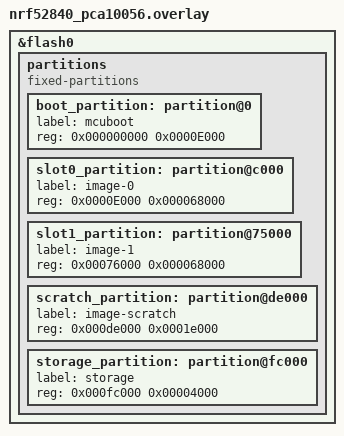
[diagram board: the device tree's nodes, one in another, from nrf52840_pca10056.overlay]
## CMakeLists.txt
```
# SPDX-License-Identifier: Apache-2.0

cmake_minimum_required(VERSION 3.20.0)
find_package(Zephyr REQUIRED HINTS $ENV{ZEPHYR_BASE})
project(mcuboot)

FILE(GLOB app_sources src/*.c)
target_sources(app PRIVATE ${app_sources})

zephyr_library_link_libraries(MCUBOOT_BOOTUTIL)
```

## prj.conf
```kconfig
CONFIG_ZTEST=y
CONFIG_STDOUT_CONSOLE=y
CONFIG_FLASH=y
CONFIG_FLASH_MAP=y
CONFIG_STREAM_FLASH=y
CONFIG_IMG_MANAGER=y
CONFIG_MCUBOOT_IMG_MANAGER=y
CONFIG_IMG_BLOCK_BUF_SIZE=512
```

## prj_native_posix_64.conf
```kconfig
CONFIG_ZTEST=y
CONFIG_STDOUT_CONSOLE=y
CONFIG_FLASH=y
CONFIG_FLASH_MAP=y
CONFIG_STREAM_FLASH=y
CONFIG_IMG_MANAGER=y
CONFIG_MCUBOOT_IMG_MANAGER=y
CONFIG_IMG_BLOCK_BUF_SIZE=512
CONFIG_ZTEST_NEW_API=y
```

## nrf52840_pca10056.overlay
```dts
/* Copyright (c) 2019 Nordic Semiconductor ASA
 *
 * SPDX-License-Identifier: Apache-2.0
 */

&flash0 {
	/*
	 * For more information, see:
	 * http://docs.zephyrproject.org/latest/guides/dts/index.html#flash-partitions
	 */

	partitions {
		compatible = "fixed-partitions";
		#address-cells = <1>;
		#size-cells = <1>;

		boot_partition: partition@0 {
			label = "mcuboot";
			reg = <0x000000000 0x0000E000>;
		};
		slot0_partition: partition@c000 {
			label = "image-0";
			reg = <0x0000E000 0x000068000>;
		};
		slot1_partition: partition@75000 {
			label = "image-1";
			reg = <0x00076000 0x000068000>;
		};
		scratch_partition: partition@de000 {
			label = "image-scratch";
			reg = <0x000de000 0x0001e000>;
		};
		storage_partition: partition@fc000 {
			label = "storage";
			reg = <0x000fc000 0x00004000>;
		};
	};
};
```

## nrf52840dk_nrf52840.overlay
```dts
/* Copyright (c) 2019 Nordic Semiconductor ASA
 *
 * SPDX-License-Identifier: Apache-2.0
 */

&flash0 {

	partitions {
		compatible = "fixed-partitions";
		#address-cells = <1>;
		#size-cells = <1>;

		boot_partition: partition@0 {
			label = "mcuboot";
			reg = <0x000000000 0x0000E000>;
		};
		slot0_partition: partition@c000 {
			label = "image-0";
			reg = <0x0000E000 0x000066000>;
		};
		slot1_partition: partition@73000 {
			label = "image-1";
			reg = <0x00074000 0x000066000>;
		};
		scratch_partition: partition@da000 {
			label = "image-scratch";
			reg = <0x000da000 0x0001e000>;
		};
	};
};
```

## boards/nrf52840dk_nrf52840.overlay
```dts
/delete-node/ &boot_partition;
/delete-node/ &slot0_partition;
/delete-node/ &slot1_partition;

&flash0 {
	partitions {
		boot_partition: partition@0 {
			compatible = "zephyr,mapped-partition";
			reg = <0x0 DT_SIZE_K(56)>;
		};

		slot0_partition: partition@e000 {
			compatible = "zephyr,mapped-partition";
			reg = <0xe000 DT_SIZE_K(468)>;
		};

		slot1_partition: partition@83000 {
			compatible = "zephyr,mapped-partition";
			reg = <0x83000 DT_SIZE_K(468)>;
		};
	};
};

/ {
	chosen {
		/*
		 * Set the slot0_partition as the active slot.
		 * The code will not be linked to slot1_partition, because the
		 * USE_DT_CODE_PARTITION Kconfig option is not set.
		 * The code will in fact use the boot_partition, but the build
		 * will not check if the code fits inside it.
		 * This check needs to be performed manually.
		 */
		zephyr,code-partition = &slot0_partition;
	};
};
```

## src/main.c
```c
/*
 * Copyright (c) 2017 Nordic Semiconductor ASA
 *
 * SPDX-License-Identifier: Apache-2.0
 */

#include <zephyr/ztest.h>
#include <zephyr/storage/flash_map.h>
#include <bootutil/bootutil_public.h>
#include <zephyr/dfu/mcuboot.h>

#define SLOT0_PARTITION		slot0_partition
#define SLOT1_PARTITION		slot1_partition

#define SLOT0_PARTITION_ID	PARTITION_ID(SLOT0_PARTITION)
#define SLOT1_PARTITION_ID	PARTITION_ID(SLOT1_PARTITION)

#define BOOT_MAGIC_VAL_W0 0xf395c277
#define BOOT_MAGIC_VAL_W1 0x7fefd260
#define BOOT_MAGIC_VAL_W2 0x0f505235
#define BOOT_MAGIC_VAL_W3 0x8079b62c
#define BOOT_MAGIC_VALUES {BOOT_MAGIC_VAL_W0, BOOT_MAGIC_VAL_W1,\
			   BOOT_MAGIC_VAL_W2, BOOT_MAGIC_VAL_W3 }

ZTEST(mcuboot_interface, test_bank_erase)
{
	const struct flash_area *fa;
	uint32_t temp;
	uint32_t temp2 = 0x5a5a5a5a;
	off_t offs;
	int ret;

	ret = flash_area_open(SLOT1_PARTITION_ID, &fa);
	if (ret) {
		printf("Flash driver was not found!\n");
		return;
	}

	for (offs = 0; offs < fa->fa_size; offs += sizeof(temp)) {
		ret = flash_area_read(fa, offs, &temp, sizeof(temp));
		zassert_true(ret == 0, "Reading from flash");
		if (temp == 0xFFFFFFFF) {
			ret = flash_area_write(fa, offs, &temp2, sizeof(temp));
			zassert_true(ret == 0, "Writing to flash");
		}
	}

	zassert(boot_erase_img_bank(SLOT1_PARTITION_ID) == 0,
		"pass", "fail");

	for (offs = 0; offs < fa->fa_size; offs += sizeof(temp)) {
		ret = flash_area_read(fa, offs, &temp, sizeof(temp));
		zassert_true(ret == 0, "Reading from flash");
		zassert(temp == 0xFFFFFFFF, "pass", "fail");
	}
}

ZTEST(mcuboot_interface, test_request_upgrade)
{
	const struct flash_area *fa;
	const uint32_t expectation[6] = {
		0xffffffff,
		0xffffffff,
		BOOT_MAGIC_VAL_W0,
		BOOT_MAGIC_VAL_W1,
		BOOT_MAGIC_VAL_W2,
		BOOT_MAGIC_VAL_W3
	};
	uint32_t readout[ARRAY_SIZE(expectation)];
	int ret;

	ret = flash_area_open(SLOT1_PARTITION_ID, &fa);
	if (ret) {
		printf("Flash driver was not found!\n");
		return;
	}

	zassert(boot_request_upgrade(false) == 0, "pass", "fail");

	ret = flash_area_read(fa, fa->fa_size - sizeof(expectation),
			      &readout, sizeof(readout));
	zassert_true(ret == 0, "Read from flash");

	zassert(memcmp(expectation, readout, sizeof(expectation)) == 0,
		"pass", "fail");

	zassert(boot_erase_img_bank(SLOT1_PARTITION_ID) == 0,
				    "pass", "fail");

	zassert(boot_request_upgrade(true) == 0, "pass", "fail");

	ret = flash_area_read(fa, fa->fa_size - sizeof(expectation),
			      &readout, sizeof(readout));
	zassert_true(ret == 0, "Read from flash");

	zassert(memcmp(&expectation[2], &readout[2], sizeof(expectation) -
		       2 * sizeof(expectation[0])) == 0, "pass", "fail");

	zassert_equal(1, readout[0] & 0xff, "confirmation error");
}

ZTEST(mcuboot_interface, test_write_confirm)
{
	const uint32_t img_magic[4] = BOOT_MAGIC_VALUES;
	uint32_t readout[ARRAY_SIZE(img_magic)];
	uint8_t flag[BOOT_MAX_ALIGN];
	const struct flash_area *fa;
	int ret;

	flag[0] = 0x01;
	memset(&flag[1], 0xff, sizeof(flag) - 1);

	ret = flash_area_open(SLOT0_PARTITION_ID, &fa);
	if (ret) {
		printf("Flash driver was not found!\n");
		return;
	}

	/*
	 * Under normal circumstances, it is not allowed to erase the active
	 * slot. However, since the USE_DT_CODE_PARTITION Kconfig option is
	 * not set, the code will in fact use the boot_partition.
	 * As a result, it is possible to erase the slot0_partition, which
	 * leads to more repeatable test results.
	 */
	zassert(boot_erase_img_bank(SLOT0_PARTITION_ID) == 0,
		"pass", "fail");

	ret = flash_area_read(fa, fa->fa_size - sizeof(img_magic),
			      &readout, sizeof(img_magic));
	zassert_true(ret == 0, "Read from flash");

	if (memcmp(img_magic, readout, sizeof(img_magic)) != 0) {
		ret = flash_area_write(fa, fa->fa_size - 16,
				       img_magic, 16);
		zassert_true(ret == 0, "Write to flash");
	}

	/* set copy-done flag */
	ret = flash_area_write(fa, fa->fa_size - 32, &flag, sizeof(flag));
	zassert_true(ret == 0, "Write to flash");

	/*
	 * Set the confirmed flag on the active slot.
	 * This will mark the slot0_partition as confirmed, even though
	 * the code uses the boot_partition, because whenever MCUboot is used,
	 * the USE_DT_CODE_PARTITION Kconfig option is set.
	 */
	ret = boot_write_img_confirmed();
	zassert(ret == 0, "pass", "fail (%d)", ret);

	ret = flash_area_read(fa, fa->fa_size - 24, readout,
			      sizeof(readout[0]));
	zassert_true(ret == 0, "Read from flash");

	zassert_equal(1, readout[0] & 0xff, "confirmation error");
}

ZTEST_SUITE(mcuboot_interface, NULL, NULL, NULL, NULL, NULL);
```
